# M55M1 register map
File version: 1.0
Registers are 32-bit, read-write, reset 0x0 unless marked. A register's access mark holds for its fields unless they carry their own. Offsets are from the block's base; [hi:lo] are bit positions; {n}, {i} and the like mark numbered series; 'fields as' and 'values as' point back to an identical list.

## SYS (part 2 of 3) — SYS Register Map
Base 0x40000000
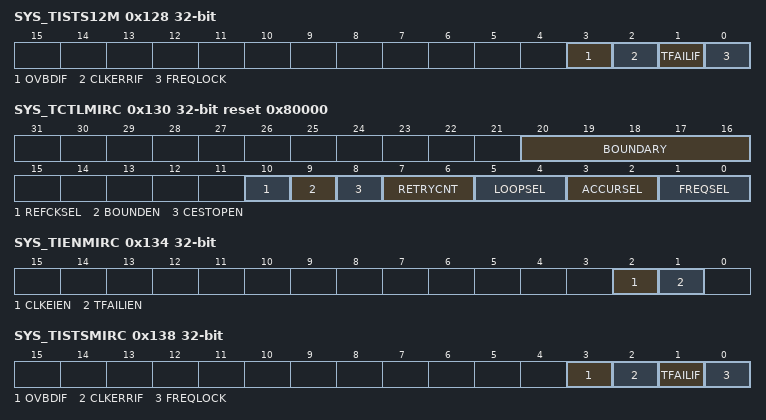
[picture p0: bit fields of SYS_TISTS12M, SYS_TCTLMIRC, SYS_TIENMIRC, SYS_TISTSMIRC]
0x128 SYS_TISTS12M — HIRC 12M Trim Interrupt Status Register
  [3] OVBDIF — Over Boundary Status. When the over boundary function is set, if there occurs the over boundary condition, this flag will be set. This is a status bit and doesn't trigger any interrupt. Note: Write 1 to clear this bit to 0.
    0=Over boundary condition did not occur; 1=Over boundary condition occurred
  [2] CLKERRIF — Clock Error Interrupt Status. When the frequency of 32.768 kHz external low speed crystal oscillator (LXT) or 12 MHz internal high speed RC oscillator (HIRC) is shift larger to unreasonable value, this bit will be set and to be an indicate that clock frequency is inaccuracy. Once this bit is set to 1, the auto trim operation stopped and FREQSEL(SYS_TCTL12M[1:0]) will be cleared to 00 by hardware automatically if CESTOPEN(SYS_TCTL12M[8]) is set to 1. If this bit is set and CLKEIEN(SYS_IRCTIEN[2]) is high, an interrupt will be triggered to notify the clock frequency is inaccuracy. Note: Write 1 to clear this bit to 0.
    0=Clock frequency is accurate; 1=Clock frequency is inaccurate
  [1] TFAILIF — Trim Failure Interrupt Status. This bit indicates that HIRC trim value update limitation count reached and the HIRC clock frequency is still not locked. Once this bit is set, the auto trim operation stopped and FREQSEL(SYS_TCTL12M[1:0]) will be cleared to 00 by hardware automatically. If this bit is set and TFAILIEN(SYS_TIEN12M[1]) is high, an interrupt will be triggered to notify that HIRC trim value update limitation count was reached. Note: Write 1 to clear this bit to 0.
    0=Trim value update limitation count did not reach; 1=Trim value update limitation count reached and HIRC frequency still not locked
  [0] FREQLOCK — HIRC Frequency Lock Status. This bit indicates the HIRC frequency is locked. This is a status bit and doesn't trigger any interrupt. This bit will be set automatically, if the frequency is lock and the RC_TRIM is enabled. Note: Write 1 to clear this bit to 0.
    0=The internal high-speed oscillator frequency is not locked at 12 MHz yet; 1=The internal high-speed oscillator frequency locked at 12 MHz
0x130 SYS_TCTLMIRC reset 0x80000 — MIRC Trim Control Register
  [20:16] BOUNDARY — Boundary Selection. Fill the boundary range from 0x1 to 0x1F, 0x0 is reserved. Note: This field is effective only when the BOUNDEN(SYS_TCTLMIRC [9]) is enabled.
  [10] REFCKSEL — Reference Clock Selection
    0=MIRC trim reference clock is from external 32.768 kHz crystal oscillator; 1=MIRC trim reference clock is from internal USB synchronous mode
  [9] BOUNDEN — Boundary Enable Bit
    0=Boundary function Disabled; 1=Boundary function Enabled
  [8] CESTOPEN — Clock Error Stop Enable Bit
    0=The trim operation is kept going if clock is inaccurate; 1=The trim operation is stopped if clock is inaccurate
  [7:6] RETRYCNT — Trim Value Update Limitation Count. This field defines that how many times the auto trim circuit will try to update the MIRC trim value before the frequency of MIRC locked. Once the MIRC locked, the internal trim value update counter will be reset. If the trim value update counter reached this limitation value and frequency of MIRC is still not locked, the auto trim operation will be disabled and FREQSEL will be cleared to 00.
    0=Trim retry count limitation is 64 loops; 1=Trim retry count limitation is 128 loops; 2=Trim retry count limitation is 256 loops; 3=Trim retry count limitation is 512 loops
  [5:4] LOOPSEL — Trim Calculation Loop Selection. This field defines that trim value calculation is based on how many reference clocks. Note: For example, if LOOPSEL is set as 00, auto trim circuit will calculate trim value based on the average frequency difference in 4 clocks of reference clock.
    0=Trim value calculation is based on average difference in 4 clocks of reference clock; 1=Trim value calculation is based on average difference in 8 clocks of reference clock; 2=Trim value calculation is based on average difference in 16 clocks of reference clock; 3=Trim value calculation is based on average difference in 32 clocks of reference clock
  [3:2] ACCURSEL — Trim Accuracy Selection. This field indicates the target frequency accuracy of 1 MHz internal high speed RC oscillator (MIRC) auto trim.
    0=Accuracy is +-0.25% deviation within all temperature ranges; 1=Accuracy is +-0.50% deviation within all temperature ranges; 2=Accuracy is +-0.75% deviation within all temperature ranges; 3=Accuracy is +-1% deviation within all temperature ranges
  [1:0] FREQSEL — Trim Frequency Selection. This field indicates the target frequency of 1 MHz internal high speed RC oscillator (MIRC) auto trim. During auto trim operation, if clock error detected with CESTOPEN is set to 1 or trim retry limitation count reached, this field will be cleared to 00 automatically.
    0=Disable MIRC auto trim function; 1=Enable MIRC auto trim function and trim MIRC to 1 MHz
0x134 SYS_TIENMIRC — MIRC Trim Interrupt Enable Register
  [2] CLKEIEN — Clock Error Interrupt Enable Bit. This bit controls if CPU would get an interrupt while clock is inaccuracy during auto trim operation. If this bit is set to1, and CLKERRIF(SYS_TISTSMIRC[2]) is set during auto trim operation, an interrupt will be triggered to notify the clock frequency is inaccuracy.
    0=Disable CLKERRIF(SYS_TISTSMIRC[2]) status to trigger an interrupt to CPU; 1=Enable CLKERRIF(SYS_TISTSMIRC[2]) status to trigger an interrupt to CPU
  [1] TFAILIEN — Trim Failure Interrupt Enable Bit. This bit controls if an interrupt will be triggered while MIRC trim value update limitation count reached and MIRC frequency still not locked on target frequency set by FREQSEL(SYS_TCTLMIRC[1:0]). If this bit is high and TFAILIF(SYS_TSTSMIRC[1]) is set during auto trim operation, an interrupt will be triggered to notify that MIRC trim value update limitation count was reached.
    0=Disable TFAILIF(SYS_TISTSMIRC[1]) status to trigger an interrupt to CPU; 1=Enable TFAILIF(SYS_TISTSMIRC[1]) status to trigger an interrupt to CPU
0x138 SYS_TISTSMIRC — MIRC Trim Interrupt Status Register
  [3] OVBDIF — Over Boundary Status. When the over boundary function is set, if there occurs the over boundary condition, this flag will be set. This is a status bit and doesn't trigger any interrupt. Note: Write 1 to clear this bit to 0.
    values as SYS_TISTS12M.OVBDIF
  [2] CLKERRIF — Clock Error Interrupt Status. When the frequency of 32.768 kHz external low speed crystal oscillator (LXT) or internal high speed RC oscillator (MIRC) is shift larger to unreasonable value, this bit will be set and to be an indicate that clock frequency is inaccuracy. Once this bit is set to 1, the auto trim operation stopped and FREQSEL(SYS_TCTLMIRC[1:0]) will be cleared to 00 by hardware automatically if CESTOPEN(SYS_TCTLMIRC[8]) is set to 1. If this bit is set and CLKEIEN(SYS_TIENMIRC[2]) is high, an interrupt will be triggered to notify the clock frequency is inaccuracy. Note: Write 1 to clear this bit to 0.
    values as SYS_TISTS12M.CLKERRIF
  [1] TFAILIF — Trim Failure Interrupt Status. This bit indicates that MIRC trim value update limitation count reached and the MIRC clock frequency is still not locked. Once this bit is set, the auto trim operation stopped and FREQSEL(SYS_TCTLMIRC[1:0]) will be cleared to 00 by hardware automatically. If this bit is set and TFAILIEN(SYS_TIENMIRC[1]) is high, an interrupt will be triggered to notify that MIRC trim value update limitation count was reached. Note: Write 1 to clear this bit to 0.
    0=Trim value update limitation count does not reach; 1=Trim value update limitation count reached and MIRC frequency still not locked
  [0] FREQLOCK — MIRC Frequency Lock Status. This bit indicates the MIRC frequency is locked. This is a status bit and doesn't trigger any interrupt. This bit will be set automatically, if the frequency is lock and the RC_TRIM is enabled. Note: Write 1 to clear this bit to 0.
    0=The internal high-speed oscillator frequency is not locked at 1 MHz; 1=The internal high-speed oscillator frequency locked at 1 MHz
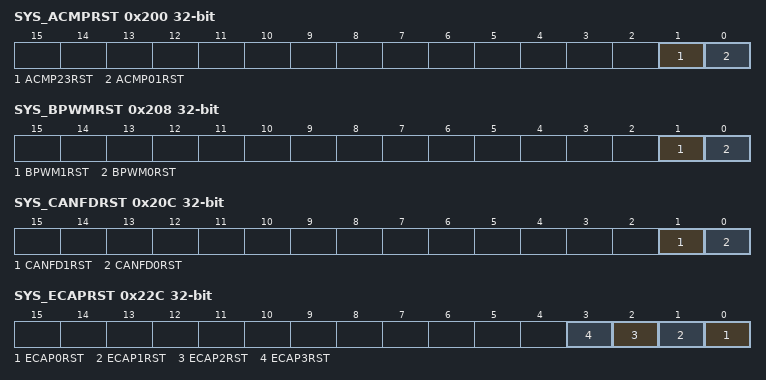
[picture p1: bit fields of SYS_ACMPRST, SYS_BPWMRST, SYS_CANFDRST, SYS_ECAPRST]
0x200 SYS_ACMPRST — ACMP Reset Control Register
  [1] ACMP23RST — ACMP2/3 Controller Reset (Write Protect). Setting this bit to 1 will generate a reset signal to the ACMP2/3. User needs to set this bit to 0 to release from reset state. Note 1: This bit is write protected. Refer to the SYS_REGLCTL register. Note 2: This bit is not retained when D0 power is turned off.
    0=ACMP2/3 controller normal operation; 1=ACMP2/3 controller reset
  [0] ACMP01RST — ACMP0/1 Controller Reset (Write Protect). Setting this bit to 1 will generate a reset signal to the ACMP0/1. User needs to set this bit to 0 to release from reset state. Note 1: This bit is write protected. Refer to the SYS_REGLCTL register. Note 2: This bit is not retained when D0 power is turned off.
    0=ACMP0/1 controller normal operation; 1=ACMP0/1 controller reset
0x204 SYS_AWFRST — AWF Reset Control Register
  [0] AWF0RST — AWF0 Controller Reset (Write Protect). Setting this bit to 1 will generate a reset signal to the AWF0. User needs to set this bit to 0 to release from reset state. Note 1: This bit is write protected. Refer to the SYS_REGLCTL register. Note 2: This bit is not retained when D0 power is turned off.
    0=AWF0 controller normal operation; 1=AWF0 controller reset
0x208 SYS_BPWMRST — BPWM Reset Control Register
  [1] BPWM1RST — BPWMx Controller Reset (Write Protect). Setting this bit to 1 will generate a reset signal to the BPWMx. User needs to set this bit to 0 to release from reset state. Note 1: This bit is write protected. Refer to the SYS_REGLCTL register. Note 2: This bit is not retained when D0 power is turned off.
    0=BPWMx controller normal operation; 1=BPWMx controller reset
  [0] BPWM0RST — BPWMx Controller Reset (Write Protect). Setting this bit to 1 will generate a reset signal to the BPWMx. User needs to set this bit to 0 to release from reset state. Note 1: This bit is write protected. Refer to the SYS_REGLCTL register. Note 2: This bit is not retained when D0 power is turned off.
    values as BPWM1RST
0x20C SYS_CANFDRST — CANFD Reset Control Register
  [1] CANFD1RST — CANFDx Controller Reset (Write Protect). Setting this bit to 1 will generate a reset signal to the CANFDx. User needs to set this bit to 0 to release from reset state. Note 1: This bit is write protected. Refer to the SYS_REGLCTL register. Note 2: This bit is not retained when D0 power is turned off.
    0=CANFDx controller normal operation; 1=CANFDx controller reset
  [0] CANFD0RST — CANFDx Controller Reset (Write Protect). Setting this bit to 1 will generate a reset signal to the CANFDx. User needs to set this bit to 0 to release from reset state. Note 1: This bit is write protected. Refer to the SYS_REGLCTL register. Note 2: This bit is not retained when D0 power is turned off.
    values as CANFD1RST
0x210 SYS_CCAPRST — CCAP Reset Control Register
  [0] CCAP0RST — CCAPx Controller Reset (Write Protect). Setting this bit to 1 will generate a reset signal to the CCAPx. User needs to set this bit to 0 to release from reset state. Note 1: This bit is write protected. Refer to the SYS_REGLCTL register. Note 2: This bit is not retained when D0 power is turned off.
    0=CCAPx controller normal operation; 1=CCAPx controller reset
0x214 SYS_CRCRST — CRC Reset Control Register
  [0] CRC0RST — CRCx Controller Reset (Write Protect). Setting this bit to 1 will generate a reset signal to the CRCx. User needs to set this bit to 0 to release from reset state. Note 1: This bit is write protected. Refer to the SYS_REGLCTL register. Note 2: This bit is not retained when D0 power is turned off.
    0=CRCx controller normal operation; 1=CRCx controller reset
0x218 SYS_CRYPTORST — CRYPTO Reset Control Register
  [0] CRYPTO0RST — CRYPTOx Controller Reset (Write Protect). Setting this bit to 1 will generate a reset signal to the CRYPTOx. User needs to set this bit to 0 to release from reset state. Note 1: This bit is write protected. Refer to the SYS_REGLCTL register. Note 2: This bit is not retained when D0 power is turned off.
    0=CRYPTOx controller normal operation; 1=CRYPTOx controller reset
0x21C SYS_DACRST — DAC Reset Control Register
  [0] DAC01RST — DAC0/1 Controller Reset (Write Protect). Setting this bit to 1 will generate a reset signal to the DAC0/1. User needs to set this bit to 0 to release from reset state. Note 1: This bit is write protected. Refer to the SYS_REGLCTL register. Note 2: This bit is not retained when D0 power is turned off.
    0=DAC0/1 controller normal operation; 1=DAC0/1 controller reset
0x220 SYS_DMICRST — DMIC Reset Control Register
  [0] DMIC0RST — DMICx Controller Reset (Write Protect). Setting this bit to 1 will generate a reset signal to the DMICx. User needs to set this bit to 0 to release from reset state. Note 1: This bit is write protected. Refer to the SYS_REGLCTL register. Note 2: This bit is not retained when D0 power is turned off.
    0=DMICx controller normal operation; 1=DMICx controller reset
0x224 SYS_EADCRST — EADC Reset Control Register
  [0] EADC0RST — EADCx Controller Reset (Write Protect). Setting this bit to 1 will generate a reset signal to the EADCx. User needs to set this bit to 0 to release from reset state. Note 1: This bit is write protected. Refer to the SYS_REGLCTL register. Note 2: This bit is not retained when D0 power is turned off.
    0=EADCx controller normal operation; 1=EADCx controller reset
0x228 SYS_EBIRST — EBI Reset Control Register
  [0] EBI0RST — EBIx Controller Reset (Write Protect). Setting this bit to 1 will generate a reset signal to the EBIx. User needs to set this bit to 0 to release from reset state. Note 1: This bit is write protected. Refer to the SYS_REGLCTL register. Note 2: This bit is not retained when D0 power is turned off.
    0=EBIx controller normal operation; 1=EBIx controller reset
0x22C SYS_ECAPRST — ECAP Reset Control Register
  [all] fields
    0=ECAPx controller normal operation; 1=ECAPx controller reset
  [n] ECAP{n}RST (n=0..3) — ECAPx Controller Reset (Write Protect). Setting this bit to 1 will generate a reset signal to the ECAPx. User needs to set this bit to 0 to release from reset state. Note 1: This bit is write protected. Refer to the SYS_REGLCTL register. Note 2: This bit is not retained when D0 power is turned off.
0x230 SYS_EMACRST — EMAC Reset Control Register
  [0] EMAC0RST — EMACx Controller Reset (Write Protect). Setting this bit to 1 will generate a reset signal to the EMACx. User needs to set this bit to 0 to release from reset state. Note 1: This bit is write protected. Refer to the SYS_REGLCTL register. Note 2: This bit is not retained when D0 power is turned off.
    0=EMACx controller normal operation; 1=EMACx controller reset
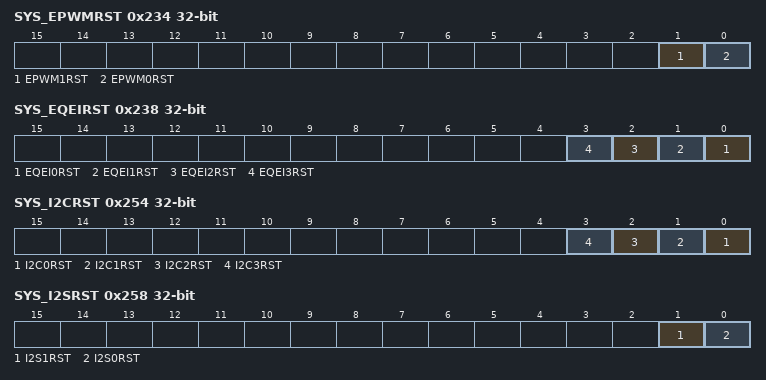
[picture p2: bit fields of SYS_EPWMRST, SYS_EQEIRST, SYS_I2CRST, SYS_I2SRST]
0x234 SYS_EPWMRST — EPWM Reset Control Register
  [1] EPWM1RST — EPWMx Controller Reset (Write Protect). Setting this bit to 1 will generate a reset signal to the EPWMx. User needs to set this bit to 0 to release from reset state. Note 1: This bit is write protected. Refer to the SYS_REGLCTL register. Note 2: This bit is not retained when D0 power is turned off.
    0=EPWMx controller normal operation; 1=EPWMx controller reset
  [0] EPWM0RST — EPWMx Controller Reset (Write Protect). Setting this bit to 1 will generate a reset signal to the EPWMx. User needs to set this bit to 0 to release from reset state. Note 1: This bit is write protected. Refer to the SYS_REGLCTL register. Note 2: This bit is not retained when D0 power is turned off.
    values as EPWM1RST
0x238 SYS_EQEIRST — EQEI Reset Control Register
  [all] fields
    0=EQEIx controller normal operation; 1=EQEIx controller reset
  [n] EQEI{n}RST (n=0..3) — EQEIx Controller Reset (Write Protect). Setting this bit to 1 will generate a reset signal to the EQEIx. User needs to set this bit to 0 to release from reset state. Note 1: This bit is write protected. Refer to the SYS_REGLCTL register. Note 2: This bit is not retained when D0 power is turned off.
0x23C SYS_FMCRST — FMC Reset Control Register
  [0] FMC0RST — FMCx Controller Reset (Write Protect). Setting this bit to 1 will generate a reset signal to the FMCx. User needs to set this bit to 0 to release from reset state. Note 1: This bit is write protected. Refer to the SYS_REGLCTL register. Note 2: This bit is not retained when D0 power is turned off.
    0=FMCx controller normal operation; 1=FMCx controller reset
0x240 SYS_GDMARST — GDMA Reset Control Register
  [0] GDMA0RST — GDMAx Controller Reset (Write Protect). Setting this bit to 1 will generate a reset signal to the GDMAx. User needs to set this bit to 0 to release from reset state. Note 1: This bit is write protected. Refer to the SYS_REGLCTL register. Note 2: This bit is not retained when D0 power is turned off.
    0=GDMAx controller normal operation; 1=GDMAx controller reset
0x244 SYS_GPIORST — GPIO Reset Control Register
  [0] GPIO0RST — GPIOx Controller Reset (Write Protect). Setting this bit to 1 will generate a reset signal to the GPIOx. User needs to set this bit to 0 to release from reset state. Note 1: This bit is write protected. Refer to the SYS_REGLCTL register. Note 2: This bit is not retained when D0 power is turned off.
    0=GPIOx controller normal operation; 1=GPIOx controller reset
0x248 SYS_HSOTGRST — HSOTG Reset Control Register
  [0] HSOTG0RST — HSOTGx Controller Reset (Write Protect). Setting this bit to 1 will generate a reset signal to the HSOTGx. User needs to set this bit to 0 to release from reset state. Note 1: This bit is write protected. Refer to the SYS_REGLCTL register. Note 2: This bit is not retained when D0 power is turned off.
    0=HSOTGx controller normal operation; 1=HSOTGx controller reset
0x24C SYS_HSUSBDRST — HSUSBD Reset Control Register
  [0] HSUSBD0RST — HSUSBDx Controller Reset (Write Protect). Setting this bit to 1 will generate a reset signal to the HSUSBDx. User needs to set this bit to 0 to release from reset state. Note 1: This bit is write protected. Refer to the SYS_REGLCTL register. Note 2: This bit is not retained when D0 power is turned off.
    0=HSUSBDx controller normal operation; 1=HSUSBDx controller reset
0x250 SYS_HSUSBHRST — HSUSBH Reset Control Register
  [0] HSUSBH0RST — HSUSBHx Controller Reset (Write Protect). Setting this bit to 1 will generate a reset signal to the HSUSBHx. User needs to set this bit to 0 to release from reset state. Note 1: This bit is write protected. Refer to the SYS_REGLCTL register. Note 2: This bit is not retained when D0 power is turned off.
    0=HSUSBHx controller normal operation; 1=HSUSBHx controller reset
0x254 SYS_I2CRST — I2C Reset Control Register
  [all] fields
    0=I2Cx controller normal operation; 1=I2Cx controller reset
  [n] I2C{n}RST (n=0..3) — I2Cx Controller Reset (Write Protect). Setting this bit to 1 will generate a reset signal to the I2Cx. User needs to set this bit to 0 to release from reset state. Note 1: This bit is write protected. Refer to the SYS_REGLCTL register. Note 2: This bit is not retained when D0 power is turned off.
0x258 SYS_I2SRST — I2S Reset Control Register
  [1] I2S1RST — I2Sx Controller Reset (Write Protect). Setting this bit to 1 will generate a reset signal to the I2Sx. User needs to set this bit to 0 to release from reset state. Note 1: This bit is write protected. Refer to the SYS_REGLCTL register. Note 2: This bit is not retained when D0 power is turned off.
    0=I2Sx controller normal operation; 1=I2Sx controller reset
  [0] I2S0RST — I2Sx Controller Reset (Write Protect). Setting this bit to 1 will generate a reset signal to the I2Sx. User needs to set this bit to 0 to release from reset state. Note 1: This bit is write protected. Refer to the SYS_REGLCTL register. Note 2: This bit is not retained when D0 power is turned off.
    0=I2Sx controller normal operation; 1=I2Sx controller reset
0x25C SYS_I3CRST — I3C Reset Control Register
  [0] I3C0RST — I3Cx Controller Reset (Write Protect). Setting this bit to 1 will generate a reset signal to the I3Cx. User needs to set this bit to 0 to release from reset state. Note 1: This bit is write protected. Refer to the SYS_REGLCTL register. Note 2: This bit is not retained when D0 power is turned off.
    0=I3Cx controller normal operation; 1=I3Cx controller reset
0x260 SYS_KDFRST — KDF Reset Control Register
  [0] KDF0RST — KDFx Controller Reset (Write Protect). Setting this bit to 1 will generate a reset signal to the KDFx. User needs to set this bit to 0 to release from reset state. Note 1: This bit is write protected. Refer to the SYS_REGLCTL register. Note 2: This bit is not retained when D0 power is turned off.
    0=KDFx controller normal operation; 1=KDFx controller reset
0x264 SYS_KPIRST — KPI Reset Control Register
  [0] KPI0RST — KPIx Controller Reset (Write Protect). Setting this bit to 1 will generate a reset signal to the KPIx. User needs to set this bit to 0 to release from reset state. Note 1: This bit is write protected. Refer to the SYS_REGLCTL register. Note 2: This bit is not retained when D0 power is turned off.
    0=KPIx controller normal operation; 1=KPIx controller reset
0x268 SYS_KSRST — KS Reset Control Register
  [0] KS0RST — KSx Controller Reset (Write Protect). Setting this bit to 1 will generate a reset signal to the KSx. User needs to set this bit to 0 to release from reset state. Note 1: This bit is write protected. Refer to the SYS_REGLCTL register. Note 2: This bit is not retained when D0 power is turned off.
    0=KSx controller normal operation; 1=KSx controller reset
0x26C SYS_LPADCRST — Low Power ADC Reset Control Register
  [0] LPADC0RST — LPADCx Controller Reset (Write Protect). Setting this bit to 1 will generate a reset signal to the LPADCx. User needs to set this bit to 0 to release from reset state. Note 1: This bit is write protected. Refer to the SYS_REGLCTL register. Note 2: This bit is not retained when D0 power is turned off.
    0=LPADCx controller normal operation; 1=LPADCx controller reset
0x270 SYS_LPPDMARST — Low Power PDMA Reset Control Register
  [0] LPPDMA0RST — LPPDMAx Controller Reset (Write Protect). Setting this bit to 1 will generate a reset signal to the LPPDMAx. User needs to set this bit to 0 to release from reset state. Note 1: This bit is write protected. Refer to the SYS_REGLCTL register. Note 2: This bit is not retained when D0 power is turned off.
    0=LPPDMAx controller normal operation; 1=LPPDMAx controller reset
0x274 SYS_LPGPIORST — Low Power GPIO Reset Control Register
  [0] LPGPIO0RST — LPGPIOx Controller Reset (Write Protect). Setting this bit to 1 will generate a reset signal to the LPGPIOx. User needs to set this bit to 0 to release from reset state. Note 1: This bit is write protected. Refer to the SYS_REGLCTL register. Note 2: This bit is not retained when D0 power is turned off.
    0=LPGPIOx controller normal operation; 1=LPGPIOx controller reset
0x278 SYS_LPI2CRST — Low Power I2C Reset Control Register
  [0] LPI2C0RST — LPI2Cx Controller Reset (Write Protect). Setting this bit to 1 will generate a reset signal to the LPI2Cx. User needs to set this bit to 0 to release from reset state. Note 1: This bit is write protected. Refer to the SYS_REGLCTL register. Note 2: This bit is not retained when D0 power is turned off.
    0=LPI2Cx controller normal operation; 1=LPI2Cx controller reset
0x27C SYS_LPSPIRST — Low Power SPI Reset Control Register
  [0] LPSPI0RST — LPSPIx Controller Reset (Write Protect). Setting this bit to 1 will generate a reset signal to the LPSPIx. User needs to set this bit to 0 to release from reset state. Note 1: This bit is write protected. Refer to the SYS_REGLCTL register. Note 2: This bit is not retained when D0 power is turned off.
    0=LPSPIx controller normal operation; 1=LPSPIx controller reset
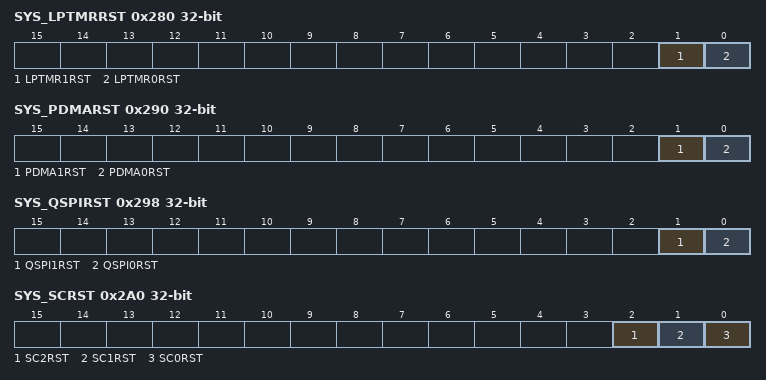
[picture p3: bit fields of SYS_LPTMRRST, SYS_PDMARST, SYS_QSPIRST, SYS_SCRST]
0x280 SYS_LPTMRRST — Low Power TMR Reset Control Register
  [1] LPTMR1RST — LPTMRx Controller Reset (Write Protect). Setting this bit to 1 will generate a reset signal to the LPTMRx. User needs to set this bit to 0 to release from reset state. Note 1: This bit is write protected. Refer to the SYS_REGLCTL register. Note 2: This bit is not retained when D0 power is turned off.
    0=LPTMRx controller normal operation; 1=LPTMRx controller reset
  [0] LPTMR0RST — LPTMRx Controller Reset (Write Protect). Setting this bit to 1 will generate a reset signal to the LPTMRx. User needs to set this bit to 0 to release from reset state. Note 1: This bit is write protected. Refer to the SYS_REGLCTL register. Note 2: This bit is not retained when D0 power is turned off.
    values as LPTMR1RST
0x284 SYS_LPUARTRST — Low Power UART Reset Control Register
  [0] LPUART0RST — LPUARTx Controller Reset (Write Protect). Setting this bit to 1 will generate a reset signal to the LPUARTx. User needs to set this bit to 0 to release from reset state. Note 1: This bit is write protected. Refer to the SYS_REGLCTL register. Note 2: This bit is not retained when D0 power is turned off.
    0=LPUARTx controller normal operation; 1=LPUARTx controller reset
0x288 SYS_OTFCRST — OTFC Reset Control Register
  [0] OTFC0RST — OTFCx Controller Reset (Write Protect). Setting this bit to 1 will generate a reset signal to the OTFCx. User needs to set this bit to 0 to release from reset state. Note 1: This bit is write protected. Refer to the SYS_REGLCTL register. Note 2: This bit is not retained when D0 power is turned off.
    0=OTFCx controller normal operation; 1=OTFCx controller reset
0x28C SYS_OTGRST — OTG Reset Control Register
  [0] OTG0RST — OTGx Controller Reset (Write Protect). Setting this bit to 1 will generate a reset signal to the OTGx. User needs to set this bit to 0 to release from reset state. Note 1: This bit is write protected. Refer to the SYS_REGLCTL register. Note 2: This bit is not retained when D0 power is turned off.
    0=OTGx controller normal operation; 1=OTGx controller reset
0x290 SYS_PDMARST — PDMA Reset Control Register
  [1] PDMA1RST — PDMAx Controller Reset (Write Protect). Setting this bit to 1 will generate a reset signal to the PDMAx. User needs to set this bit to 0 to release from reset state. Note 1: This bit is write protected. Refer to the SYS_REGLCTL register. Note 2: This bit is not retained when D0 power is turned off.
    0=PDMAx controller normal operation; 1=PDMAx controller reset
  [0] PDMA0RST — PDMAx Controller Reset (Write Protect). Setting this bit to 1 will generate a reset signal to the PDMAx. User needs to set this bit to 0 to release from reset state. Note 1: This bit is write protected. Refer to the SYS_REGLCTL register. Note 2: This bit is not retained when D0 power is turned off.
    values as PDMA1RST
0x294 SYS_PSIORST — PSIO Reset Control Register
  [0] PSIO0RST — PSIOx Controller Reset (Write Protect). Setting this bit to 1 will generate a reset signal to the PSIOx. User needs to set this bit to 0 to release from reset state. Note 1: This bit is write protected. Refer to the SYS_REGLCTL register. Note 2: This bit is not retained when D0 power is turned off.
    0=PSIOx controller normal operation; 1=PSIOx controller reset
0x298 SYS_QSPIRST — QSPI Reset Control Register
  [1] QSPI1RST — QSPIx Controller Reset (Write Protect). Setting this bit to 1 will generate a reset signal to the QSPIx. User needs to set this bit to 0 to release from reset state. Note 1: This bit is write protected. Refer to the SYS_REGLCTL register. Note 2: This bit is not retained when D0 power is turned off.
    0=QSPIx controller normal operation; 1=QSPIx controller reset
  [0] QSPI0RST — QSPIx Controller Reset (Write Protect). Setting this bit to 1 will generate a reset signal to the QSPIx. User needs to set this bit to 0 to release from reset state. Note 1: This bit is write protected. Refer to the SYS_REGLCTL register. Note 2: This bit is not retained when D0 power is turned off.
    values as QSPI1RST
0x29C SYS_RTCRST — RTC Reset Control Register
  [0] RTC0RST — RTCx Controller Reset (Write Protect). Setting this bit to 1 will generate a reset signal to the RTCx. User needs to set this bit to 0 to release from reset state. Note 1: This bit is write protected. Refer to the SYS_REGLCTL register. Note 2: This bit is not retained when D0 power is turned off.
    0=RTCx controller normal operation; 1=RTCx controller reset
0x2A0 SYS_SCRST — SC Reset Control Register
  [all] fields
    0=SCx controller normal operation; 1=SCx controller reset
  [2] SC2RST — SCx Controller Reset (Write Protect). Setting this bit to 1 will generate a reset signal to the SCx. User needs to set this bit to 0 to release from reset state. Note 1: This bit is write protected. Refer to the SYS_REGLCTL register. Note 2: This bit is not retained when D0 power is turned off.
  [1] SC1RST — SCx Controller Reset (Write Protect). Setting this bit to 1 will generate a reset signal to the SCx. User needs to set this bit to 0 to release from reset state. Note 1: This bit is write protected. Refer to the SYS_REGLCTL register. Note 2: This bit is not retained when D0 power is turned off.
  [0] SC0RST — SCx Controller Reset (Write Protect). Setting this bit to 1 will generate a reset signal to the SCx. User needs to set this bit to 0 to release from reset state. Note 1: This bit is write protected. Refer to the SYS_REGLCTL register. Note 2: This bit is not retained when D0 power is turned off.
0x2A4 SYS_SCURST — SCU Reset Control Register
  [0] SCU0RST — SCUx Controller Reset (Write Protect). Setting this bit to 1 will generate a reset signal to the SCUx. User needs to set this bit to 0 to release from reset state. Note 1: This bit is write protected. Refer to the SYS_REGLCTL register. Note 2: This bit is not retained when D0 power is turned off.
    0=SCUx controller normal operation; 1=SCxU controller reset
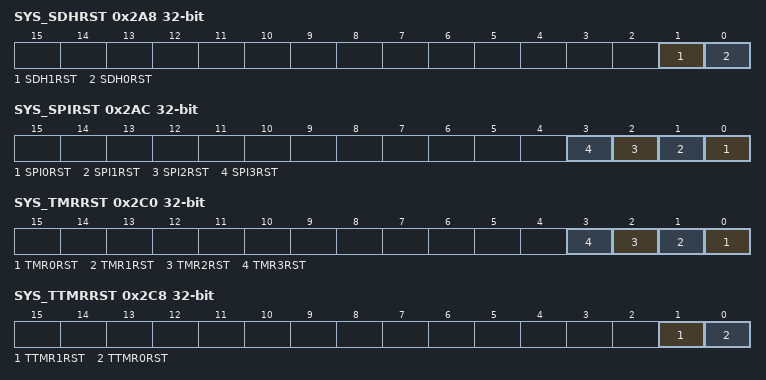
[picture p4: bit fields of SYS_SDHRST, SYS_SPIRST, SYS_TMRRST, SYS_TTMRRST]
0x2A8 SYS_SDHRST — SDH Reset Control Register
  [1] SDH1RST — SDHx Controller Reset (Write Protect). Setting this bit to 1 will generate a reset signal to the SDHx. User needs to set this bit to 0 to release from reset state. Note 1: This bit is write protected. Refer to the SYS_REGLCTL register. Note 2: This bit is not retained when D0 power is turned off.
    0=SDHx controller normal operation; 1=SDHx controller reset
  [0] SDH0RST — SDHx Controller Reset (Write Protect). Setting this bit to 1 will generate a reset signal to the SDHx. User needs to set this bit to 0 to release from reset state. Note 1: This bit is write protected. Refer to the SYS_REGLCTL register. Note 2: This bit is not retained when D0 power is turned off.
    0=SDHx controller normal operation; 1=SDHx controller reset
0x2AC SYS_SPIRST — SPI Reset Control Register
  [all] fields
    0=SPIx controller normal operation; 1=SPIx controller reset
  [n] SPI{n}RST (n=0..3) — SPIx Controller Reset (Write Protect). Setting this bit to 1 will generate a reset signal to the SPIx. User needs to set this bit to 0 to release from reset state. Note 1: This bit is write protected. Refer to the SYS_REGLCTL register. Note 2: This bit is not retained when D0 power is turned off.
0x2B0 SYS_SPIMRST — SPIM Reset Control Register
  [0] SPIM0RST — SPIMx Controller Reset (Write Protect). Setting this bit to 1 will generate a reset signal to the SPIMx. User needs to set this bit to 0 to release from reset state. Note 1: This bit is write protected. Refer to the SYS_REGLCTL register. Note 2: This bit is not retained when D0 power is turned off.
    0=SPIMx controller normal operation; 1=SPIMx controller reset
0x2C0 SYS_TMRRST — Timer Reset Control Register
  [all] fields
    0=TMRx controller normal operation; 1=TMRx controller reset
  [n] TMR{n}RST (n=0..3) — TMRx Controller Reset (Write Protect). Setting this bit to 1 will generate a reset signal to the TMRx. User needs to set this bit to 0 to release from reset state. Note 1: This bit is write protected. Refer to the SYS_REGLCTL register. Note 2: This bit is not retained when D0 power is turned off.
0x2C4 SYS_TRNGRST — TRNG Reset Control Register
  [0] TRNG0RST — TRNGx Controller Reset (Write Protect). Setting this bit to 1 will generate a reset signal to the TRNGx. User needs to set this bit to 0 to release from reset state. Note 1: This bit is write protected. Refer to the SYS_REGLCTL register. Note 2: This bit is not retained when D0 power is turned off.
    0=TRNGx controller normal operation; 1=TRNGx controller reset
0x2C8 SYS_TTMRRST — Tick Timer Reset Control Register
  [1] TTMR1RST — TTMRx Controller Reset (Write Protect). Setting this bit to 1 will generate a reset signal to the TTMRx. User needs to set this bit to 0 to release from reset state. Note 1: This bit is write protected. Refer to the SYS_REGLCTL register. Note 2: This bit is not retained when D0 power is turned off.
    0=TTMRx controller normal operation; 1=TTMRx controller reset
  [0] TTMR0RST — TTMRx Controller Reset (Write Protect). Setting this bit to 1 will generate a reset signal to the TTMRx. User needs to set this bit to 0 to release from reset state. Note 1: This bit is write protected. Refer to the SYS_REGLCTL register. Note 2: This bit is not retained when D0 power is turned off.
    values as TTMR1RST
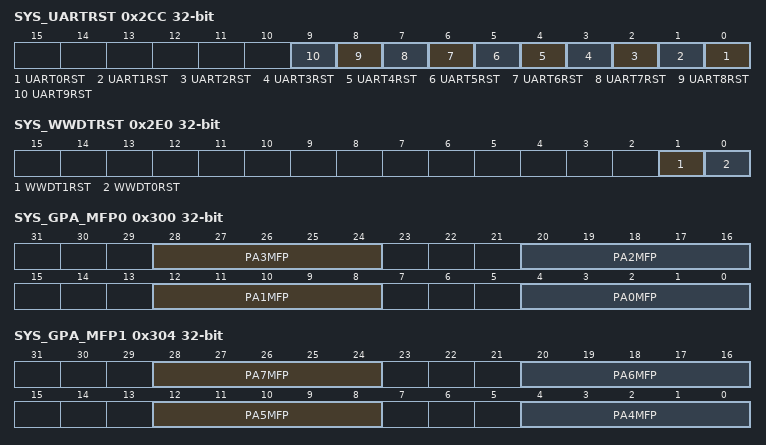
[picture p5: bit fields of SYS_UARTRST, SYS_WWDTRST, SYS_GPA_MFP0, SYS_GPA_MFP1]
0x2CC SYS_UARTRST — UART Reset Control Register
  [all] fields
    0=UARTx controller normal operation; 1=UARTx controller reset
  [n] UART{n}RST (n=0..9) — UARTx Controller Reset (Write Protect). Setting this bit to 1 will generate a reset signal to the UARTx. User needs to set this bit to 0 to release from reset state. Note 1: This bit is write protected. Refer to the SYS_REGLCTL register. Note 2: This bit is not retained when D0 power is turned off.
0x2D0 SYS_USBDRST — USB Device Reset Control Register
  [0] USBD0RST — USBDx Controller Reset (Write Protect). Setting this bit to 1 will generate a reset signal to the USBDx. User needs to set this bit to 0 to release from reset state. Note 1: This bit is write protected. Refer to the SYS_REGLCTL register. Note 2: This bit is not retained when D0 power is turned off.
    0=USBDx controller normal operation; 1=USBDx controller reset
0x2D4 SYS_USBHRST — USB Host Reset Control Register
  [0] USBH0RST — USBHx Controller Reset (Write Protect). Setting this bit to 1 will generate a reset signal to the USBHx. User needs to set this bit to 0 to release from reset state. Note 1: This bit is write protected. Refer to the SYS_REGLCTL register. Note 2: This bit is not retained when D0 power is turned off.
    0=USBHx controller normal operation; 1=USBHx controller reset
0x2D8 SYS_USCIRST — USCI Reset Control Register
  [0] USCI0RST — USCIx Controller Reset (Write Protect). Setting this bit to 1 will generate a reset signal to the USCIx. User needs to set this bit to 0 to release from reset state. Note 1: This bit is write protected. Refer to the SYS_REGLCTL register. Note 2: This bit is not retained when D0 power is turned off.
    0=USCIx controller normal operation; 1=USCIx controller reset
0x2DC SYS_UTCPDRST — UTCPD Reset Control Register
  [0] UTCPD0RST — UTCPDx Controller Reset (Write Protect). Setting this bit to 1 will generate a reset signal to the UTCPDx. User needs to set this bit to 0 to release from reset state. Note 1: This bit is write protected. Refer to the SYS_REGLCTL register. Note 2: This bit is not retained when D0 power is turned off.
    0=UTCPDx controller normal operation; 1=UTCPDx controller reset
0x2E0 SYS_WWDTRST — WWDT Reset Control Register
  [1] WWDT1RST — WWDTx Controller Reset (Write Protect). Setting this bit to 1 will generate a reset signal to the WWDTx. User needs to set this bit to 0 to release from reset state. Note 1: This bit is write protected. Refer to the SYS_REGLCTL register. Note 2: This bit is not retained when D0 power is turned off.
    0=WWDTx controller normal operation; 1=WWDTx controller reset
  [0] WWDT0RST — WWDTx Controller Reset (Write Protect). Setting this bit to 1 will generate a reset signal to the WWDTx. User needs to set this bit to 0 to release from reset state. Note 1: This bit is write protected. Refer to the SYS_REGLCTL register. Note 2: This bit is not retained when D0 power is turned off.
    values as WWDT1RST
0x300 SYS_GPA_MFP0 — GPIOA Multiple Function Control Register 0
  [28:24] PA3MFP — PA.3 Multi-function Pin Selection. Note: These bits are not retained when D2 power is turned off.
  [20:16] PA2MFP — PA.2 Multi-function Pin Selection. Note: These bits are not retained when D2 power is turned off.
  [12:8] PA1MFP — PA.1 Multi-function Pin Selection. Note: These bits are not retained when D2 power is turned off.
  [4:0] PA0MFP — PA.0 Multi-function Pin Selection. Note: These bits are not retained when D2 power is turned off.
0x304 SYS_GPA_MFP1 — GPIOA Multiple Function Control Register 1
  [28:24] PA7MFP — PA.7 Multi-function Pin Selection. Note: These bits are not retained when D2 power is turned off.
  [20:16] PA6MFP — PA.6 Multi-function Pin Selection. Note: These bits are not retained when D2 power is turned off.
  [12:8] PA5MFP — PA.5 Multi-function Pin Selection. Note: These bits are not retained when D2 power is turned off.
  [4:0] PA4MFP — PA.4 Multi-function Pin Selection. Note: These bits are not retained when D2 power is turned off.
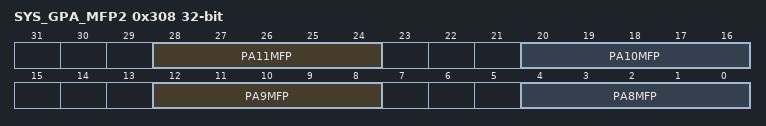
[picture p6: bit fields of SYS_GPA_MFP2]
0x308 SYS_GPA_MFP2 — GPIOA Multiple Function Control Register 2
  [28:24] PA11MFP — PA.11 Multi-function Pin Selection. Note: These bits are not retained when D2 power is turned off.
  [20:16] PA10MFP — PA.10 Multi-function Pin Selection. Note: These bits are not retained when D2 power is turned off.
  [12:8] PA9MFP — PA.9 Multi-function Pin Selection. Note: These bits are not retained when D2 power is turned off.
  [4:0] PA8MFP — PA.8 Multi-function Pin Selection. Note: These bits are not retained when D2 power is turned off.
